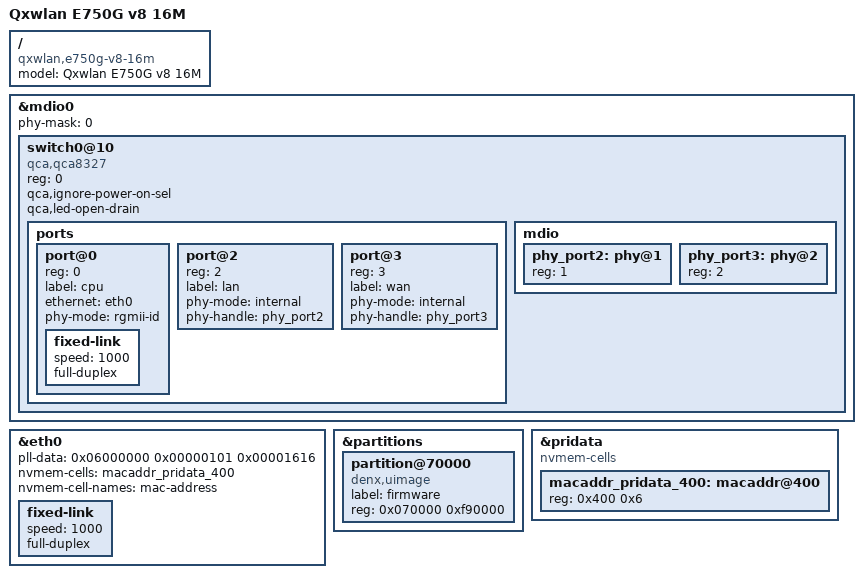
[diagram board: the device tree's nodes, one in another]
// SPDX-License-Identifier: GPL-2.0-or-later OR MIT

#include "ar9344_qxwlan_e750x.dtsi"

/ {
	model = "Qxwlan E750G v8 16M";
	compatible = "qxwlan,e750g-v8-16m", "qca,ar9344";
};

&mdio0 {
	status = "okay";

	phy-mask = <0>;

	switch0@10 {
		compatible = "qca,qca8327";
		#address-cells = <1>;
		#size-cells = <0>;

		reg = <0>;
		qca,ignore-power-on-sel;
		qca,led-open-drain;

		ports {
			#address-cells = <1>;
			#size-cells = <0>;

			port@0 {
				reg = <0>;
				label = "cpu";
				ethernet = <&eth0>;
				phy-mode = "rgmii-id";

				fixed-link {
					speed = <1000>;
					full-duplex;
				};
			};

			port@2 {
				reg = <2>;
				label = "lan";
				phy-mode = "internal";
				phy-handle = <&phy_port2>;
			};

			port@3 {
				reg = <3>;
				label = "wan";
				phy-mode = "internal";
				phy-handle = <&phy_port3>;
			};
		};

		mdio {
			#address-cells = <1>;
			#size-cells = <0>;

			phy_port2: phy@1 {
				reg = <1>;
			};

			phy_port3: phy@2 {
				reg = <2>;
			};
		};
	};
};

&eth0 {
	status = "okay";

	pll-data = <0x06000000 0x00000101 0x00001616>;

	nvmem-cells = <&macaddr_pridata_400>;
	nvmem-cell-names = "mac-address";

	fixed-link {
		speed = <1000>;
		full-duplex;
	};
};

&partitions {
	partition@70000 {
		compatible = "denx,uimage";
		label = "firmware";
		reg = <0x070000 0xf90000>;
	};
};

&pridata {
	compatible = "nvmem-cells";
	#address-cells = <1>;
	#size-cells = <1>;

	macaddr_pridata_400: macaddr@400 {
		reg = <0x400 0x6>;
	};
};
